# ATL register map
Vendor: Texas Instruments
Peripheral module from a debugger description file (folder DRA74xP_75xP_76xP_77xP).
Registers are 32-bit, access per field, reset 0x0 unless marked. A register's access mark holds for its fields unless they carry their own. Offsets are as the file gives them; lines under a group give offsets from that group; [hi:lo] are bit positions; {n}, {i} and the like mark numbered series; 'fields as' and 'values as' point back to an identical list; <NAME> marks a mode.

## ATL
0x00 ATL_REVID ro — ATL IP revision. Value is hard wired and revised for each new IP release
  [31:0] REV — Identifies the ATL revision.
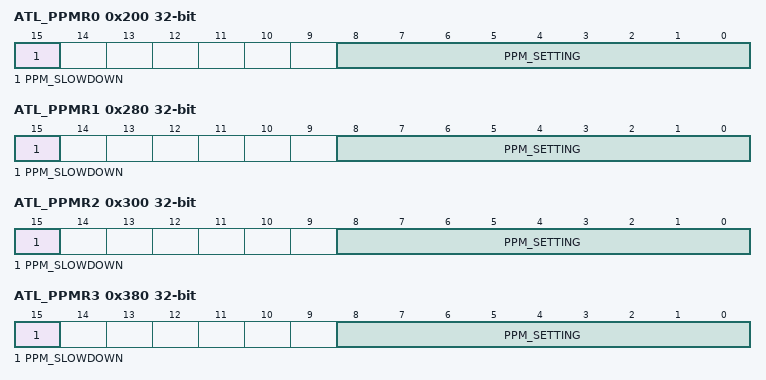
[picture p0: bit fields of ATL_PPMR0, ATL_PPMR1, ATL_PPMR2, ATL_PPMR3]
0x200 ATL_PPMR0 access not given (reset mask 0xFFFFFE00) — Parts per million register for the first ATL instance. This register is used by the adjusting circuit. The Parts-Per-Million Registers 0-2 (PPMRn) are used by the audio re-timing code to adjust the DAC clocking rate by changing the McASP clocks. The McASP high-speed clock slows down or speeds up by the PPM written to PPM_SETTING bits [8:0], which changes the DAC over-sampling clock or the frame sync and bit clocks.
  [15] PPM_SLOWDOWN rw — Part-Per-Million Slowdown
    0=Speed_up; 1=Slow_down
  [8:0] PPM_SETTING — PPM_SETTING PPM adjustment = PPMR[8:0] ÷ 2
0x204 ATL_BBSR0 ro — Baseband sample register for the first ATL instance.
  [15:0] SAMPLE_COUNT — The measuring circuit produces a 16- bit Sample Count that is stored in the BBSR register. Its inputs are the Audio IIS Word Select (AWS) and the Baseband IIS Word Select (BWS) from their respective McASP pins.
0x208 ATL_ATLCR0 — ATL configuration register for first ATL instance.
  [4:0] ATL_INTERNAL_DIVIDER rw — ATL Internal Divider. Sets ATLPCLK-to-ATCLK ratio. The ATL Internal Divider divides down the ATL master clock (ATLPCLK) to generate ATCLK.
0x210 ATL_SWEN0 — Software enable bit for the first ATL instance. The audio tracking logic (ATL) must be held in reset while the AWS, BWS, and ATPCLK mux selections are set, and while the system level clocking is configured.
  [0] SWEN rw — Software enable bit. The software must enable this bit to enable the first ATL instance.
    0=ATL0_disabled; 1=ATL0_enabled
0x214 ATL_BWSMUX0 — Select source for BWS input to first ATL instance. The ATL baseband word input can be connected to up to 15 different input sources. This register must be configured to set the McASP (or other input) desired for the first ATL instance.
  [3:0] BWSMUX rw — Baseband Word Select Mux. Selects the source for the BWS input to the first ATL instance.
    0=McASP1_FSR; 1=McASP1_FSX; 2=McASP2_FSR; {v}=McASP{v-1}_FSX (v=3..9); 10=McASP8_AHCLKX; 11=XREF_CLK3_input_pad; 12=XREF_CLK0_input_pad; 13=XREF_CLK1_input_pad; 14=XREF_CLK2_input_pad; 15=OSC1_X1_input_pad
0x218 ATL_AWSMUX0 — Select source for AWS input to the first ATL instance. The ATL audio word input can be connected to up to 15 different input sources. This register must be configured to set the McASP (or other input) desired for the first ATL instance.
  [3:0] AWSMUX rw — Audio Word Select Mux. Selects the source for the AWS input to the first ATL instance.
    values as ATL_BWSMUX0.BWSMUX
0x21C ATL_PCLKMUX0 — Select source for ATLPCLK input to all four ATL instances. The ATL clock input can be driven from with the OCP_CLK or the ATLPCLK inputs. The ATLPCLK selection register determines the final clock source for the ATL core audio tracking logic. In most use cases this will be set to the ATLPCLK input to use the system clocks shown in the device specific data manual.
  [0] PCLKMUX rw — ATLPCLK Selection Register Mux. Selects the source for the ATLPCLK input to all four ATL instances.
    0=OCP_CLK_input; 1=ATLPCLK_input
0x280 ATL_PPMR1 access not given (reset mask 0xFFFFFE00) — Parts per million register for the second ATL instance. This register is used by the adjusting circuit. The Parts-Per-Million Registers 0-2 (PPMRn) are used by the audio re-timing code to adjust the DAC clocking rate by changing the McASP clocks. The McASP high-speed clock slows down or speeds up by the PPM written to PPM_SETTING bits [8:0], which changes the DAC over-sampling clock or the frame sync and bit clocks.
  fields as ATL_PPMR0
0x284 ATL_BBSR1 ro — Baseband sample register for the second ATL instance.
  fields as ATL_BBSR0
0x288 ATL_ATLCR1 — ATL configuration register for the second ATL instance.
  fields as ATL_ATLCR0
0x290 ATL_SWEN1 — Software enable bit for the second ATL instance. The audio tracking logic (ATL) must be held in reset while the AWS, BWS, and ATPCLK mux selections are set, and while the system level clocking is configured.
  [0] SWEN rw — Software enable bit. The software must enable this bit to enable the second ATL instance.
    0=ATL1_disabled; 1=ATL1_enabled
0x294 ATL_BWSMUX1 — Select source for BWS input to the second ATL instance. The ATL baseband word input can be connected to up to 15 different input sources. This register must be configured to set the McASP (or other input) desired for the second ATL instance.
  [3:0] BWSMUX rw — Baseband Word Select Mux. Selects the source for the BWS input to the second ATL instance.
    values as ATL_BWSMUX0.BWSMUX
0x298 ATL_AWSMUX1 — Select source for AWS input to the second ATL instance. The ATL audio word input can be connected to up to 15 different input sources. This register must be configured to set the McASP (or other input) desired for the second ATL instance.
  [3:0] AWSMUX rw — Audio Word Select Mux. Selects the source for the AWS input to the second ATL instance.
    values as ATL_BWSMUX0.BWSMUX
0x29C ATL_PCLKMUX1 — Select source for ATLPCLK input to the second ATL instance. The ATL clock input can be driven from with the OCP_CLK or the ATLPCLK inputs. The ATLPCLK selection register determines the final clock source for the ATL core audio tracking logic. In most use cases this will be set to the ATLPCLK input to use the system clocks shown in the device specific data manual.
  [0] PCLKMUX rw — ATLPCLK Selection Register Mux. Selects the source for the ATLPCLK input to the second ATL instance. (Not functional).
    0=OCP_CLK_input; 1=ATLPCLK_input
0x300 ATL_PPMR2 access not given (reset mask 0xFFFFFE00) — Parts per million register for the third ATL instance. This register is used by the adjusting circuit. The Parts-Per-Million Registers 0-2 (PPMRn) are used by the audio re-timing code to adjust the DAC clocking rate by changing the McASP clocks. The McASP high-speed clock slows down or speeds up by the PPM written to PPM_SETTING bits [8:0], which changes the DAC over-sampling clock or the frame sync and bit clocks.
  fields as ATL_PPMR0
0x304 ATL_BBSR2 ro — Baseband sample register for third ATL instance.
  fields as ATL_BBSR0
0x308 ATL_ATLCR2 — ATL configuration register for the third ATL instance.
  fields as ATL_ATLCR0
0x310 ATL_SWEN2 — Software enable bit for the third ATL instance. The audio tracking logic (ATL) must be held in reset while the AWS, BWS, and ATPCLK mux selections are set, and while the system level clocking is configured.
  [0] SWEN rw — Software enable bit. The software must enable this bit to enable the third ATL instance.
    0=ATL2_disabled; 1=ATL2_enabled
0x314 ATL_BWSMUX2 — Select source for BWS input to to the third ATL instance. The ATL baseband word input can be connected to up to 15 different input sources. This register must be configured to set the McASP (or other input) desired for the third ATL instance.
  [3:0] BWSMUX rw — Baseband Word Select Mux. Selects the source for the BWS input to the third ATL instance.
    values as ATL_BWSMUX0.BWSMUX
0x318 ATL_AWSMUX2 — Select source for AWS input to the third ATL instance. The ATL audio word input can be connected to up to 15 different input sources. This register must be configured to set the McASP (or other input) desired for the third ATL instance.
  [3:0] AWSMUX rw — Audio Word Select Mux. Selects the source for the AWS input to the third ATL instance.
    values as ATL_BWSMUX0.BWSMUX
0x31C ATL_PCLKMUX2 — Select source for ATLPCLK input to the third ATL instance. The ATL clock input can be driven from with the OCP_CLK or the ATLPCLK inputs. The ATLPCLK selection register determines the final clock source for the ATL core audio tracking logic. In most use cases this will be set to the ATLPCLK input to use the system clocks shown in the device specific data manual.
  [0] PCLKMUX rw — ATLPCLK Selection Register Mux. Selects the source for the ATLPCLK input to the third instance. (Not functional).
    0=OCP_CLK_input; 1=ATLPCLK_input
0x380 ATL_PPMR3 access not given (reset mask 0xFFFFFE00) — Parts per million register fourth ATL instance. This register is used by the adjusting circuit. The Parts-Per-Million Registers 0-2 (PPMRn) are used by the audio re-timing code to adjust the DAC clocking rate by changing the McASP clocks. The McASP high-speed clock slows down or speeds up by the PPM written to PPM_SETTING bits [8:0], which changes the DAC over-sampling clock or the frame sync and bit clocks.
  fields as ATL_PPMR0
0x384 ATL_BBSR3 ro — Baseband sample register fourth ATL instance.
  fields as ATL_BBSR0
0x388 ATL_ATLCR3 — ATL configuration register fourth ATL instance.
  fields as ATL_ATLCR0
0x390 ATL_SWEN3 — Software enable bit for fourth ATL instance. The audio tracking logic (ATL) must be held in reset while the AWS, BWS, and ATPCLK mux selections are set, and while the system level clocking is configured.
  [0] SWEN rw — Software enable bit. The software must enable this bit to enable the fourth ATL instance.
    0=ATL3_disabled; 1=ATL3_enabled
0x394 ATL_BWSMUX3 — Select source for BWS input to fourth instance ATL. The ATL baseband word input can be connected to up to 15 different input sources. This register must be configured to set the McASP (or other input) desired for the fourth ATL instance.
  [3:0] BWSMUX rw — Baseband Word Select Mux. Selects the source for the BWS input to the fourth ATL instance.
    values as ATL_BWSMUX0.BWSMUX
0x398 ATL_AWSMUX3 — Select source for AWS input to fourth instance ATL. The ATL audio word input can be connected to up to 15 different input sources. This register must be configured to set the McASP (or other input) desired for the fourth ATL instance.
  [3:0] AWSMUX rw — Audio Word Select Mux. Selects the source for the AWS input to the fourth ATL instance
    values as ATL_BWSMUX0.BWSMUX
0x39C ATL_PCLKMUX3 — Select source for ATLPCLK input to fourth instance ATL. The ATL clock input can be driven from with the OCP_CLK or the ATLPCLK inputs. The ATLPCLK selection register determines the final clock source for the ATL core audio tracking logic. In most use cases this will be set to the ATLPCLK input to use the system clocks shown in the device specific data manual.
  [0] PCLKMUX rw — ATLPCLK Selection Register Mux. Selects the source for the ATLPCLK input to the fourth ATL instance. (Not functional).
    0=OCP_CLK_input; 1=ATLPCLK_input
